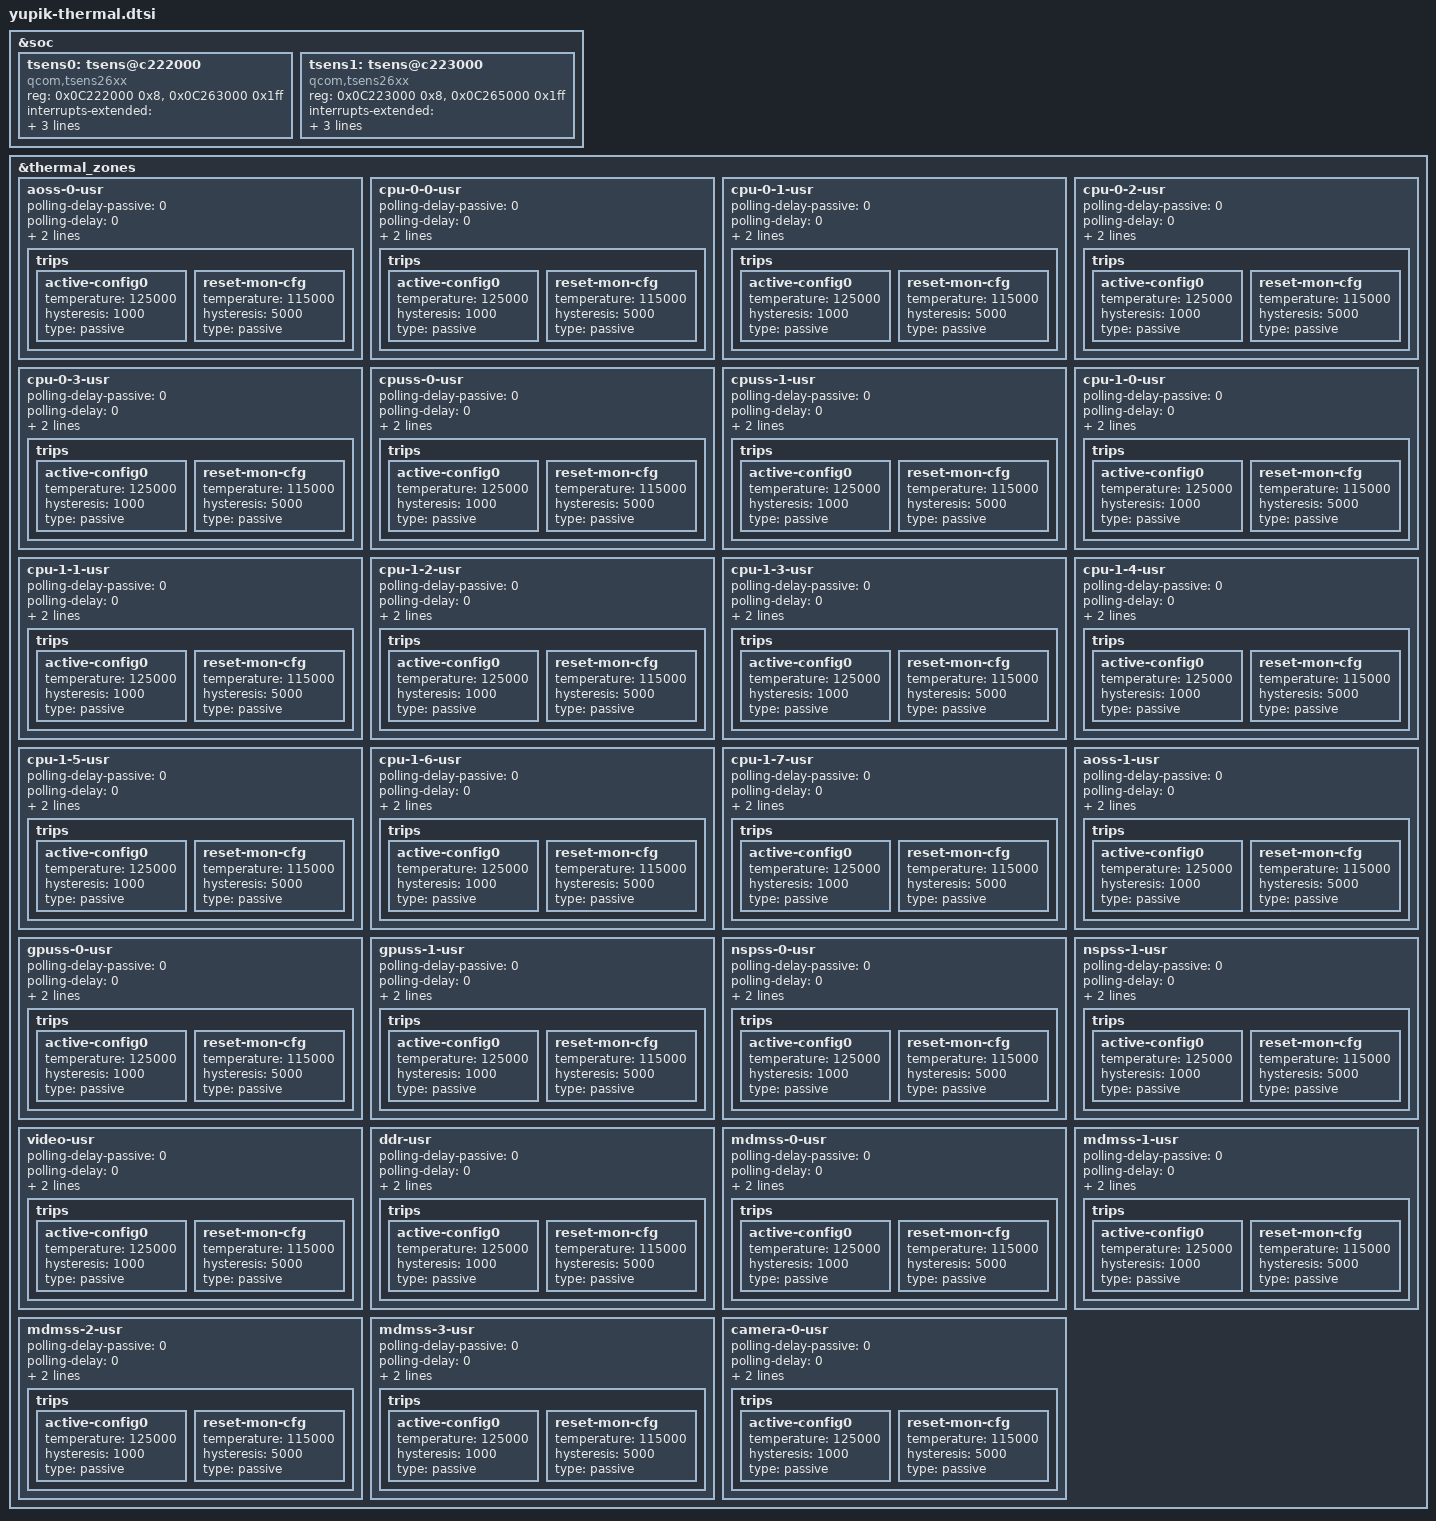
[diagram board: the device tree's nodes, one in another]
#include <dt-bindings/thermal/thermal_qti.h>

&soc {
	tsens0:tsens@c222000 {
		compatible = "qcom,tsens26xx";
		reg = <0x0C222000 0x8>,
			<0x0C263000 0x1ff>;
		reg-names = "tsens_srot_physical",
			"tsens_tm_physical";
		interrupts-extended = <&intc GIC_SPI 506 IRQ_TYPE_LEVEL_HIGH>,
				<&intc GIC_SPI 508 IRQ_TYPE_LEVEL_HIGH>,
				<&pdc 20 IRQ_TYPE_EDGE_RISING>;
		interrupt-names = "tsens-upper-lower",
				"tsens-critical",
				"tsens-0C";
		#thermal-sensor-cells = <1>;
	};

	tsens1:tsens@c223000 {
		compatible = "qcom,tsens26xx";
		reg = <0x0C223000 0x8>,
			<0x0C265000 0x1ff>;
		reg-names = "tsens_srot_physical",
			"tsens_tm_physical";
		interrupts-extended = <&intc GIC_SPI 507 IRQ_TYPE_LEVEL_HIGH>,
				<&intc GIC_SPI 509 IRQ_TYPE_LEVEL_HIGH>,
				<&pdc 21 IRQ_TYPE_EDGE_RISING>;
		interrupt-names = "tsens-upper-lower",
				"tsens-critical",
				"tsens-0C";
		#thermal-sensor-cells = <1>;
	};
};

&thermal_zones {
	aoss-0-usr {
		polling-delay-passive = <0>;
		polling-delay = <0>;
		thermal-governor = "user_space";
		thermal-sensors = <&tsens0 0>;
		trips {
			active-config0 {
				temperature = <125000>;
				hysteresis = <1000>;
				type = "passive";
			};

			reset-mon-cfg {
				temperature = <115000>;
				hysteresis = <5000>;
				type = "passive";
			};
		};
	};

	cpu-0-0-usr {
		polling-delay-passive = <0>;
		polling-delay = <0>;
		thermal-governor = "user_space";
		thermal-sensors = <&tsens0 1>;
		trips {
			active-config0 {
				temperature = <125000>;
				hysteresis = <1000>;
				type = "passive";
			};

			reset-mon-cfg {
				temperature = <115000>;
				hysteresis = <5000>;
				type = "passive";
			};
		};
	};

	cpu-0-1-usr {
		polling-delay-passive = <0>;
		polling-delay = <0>;
		thermal-governor = "user_space";
		thermal-sensors = <&tsens0 2>;
		trips {
			active-config0 {
				temperature = <125000>;
				hysteresis = <1000>;
				type = "passive";
			};

			reset-mon-cfg {
				temperature = <115000>;
				hysteresis = <5000>;
				type = "passive";
			};
		};
	};

	cpu-0-2-usr {
		polling-delay-passive = <0>;
		polling-delay = <0>;
		thermal-governor = "user_space";
		thermal-sensors = <&tsens0 3>;
		trips {
			active-config0 {
				temperature = <125000>;
				hysteresis = <1000>;
				type = "passive";
			};

			reset-mon-cfg {
				temperature = <115000>;
				hysteresis = <5000>;
				type = "passive";
			};
		};
	};

	cpu-0-3-usr {
		polling-delay-passive = <0>;
		polling-delay = <0>;
		thermal-governor = "user_space";
		thermal-sensors = <&tsens0 4>;
		trips {
			active-config0 {
				temperature = <125000>;
				hysteresis = <1000>;
				type = "passive";
			};

			reset-mon-cfg {
				temperature = <115000>;
				hysteresis = <5000>;
				type = "passive";
			};
		};
	};

	cpuss-0-usr {
		polling-delay-passive = <0>;
		polling-delay = <0>;
		thermal-governor = "user_space";
		thermal-sensors = <&tsens0 5>;
		trips {
			active-config0 {
				temperature = <125000>;
				hysteresis = <1000>;
				type = "passive";
			};

			reset-mon-cfg {
				temperature = <115000>;
				hysteresis = <5000>;
				type = "passive";
			};
		};
	};

	cpuss-1-usr {
		polling-delay-passive = <0>;
		polling-delay = <0>;
		thermal-governor = "user_space";
		thermal-sensors = <&tsens0 6>;
		trips {
			active-config0 {
				temperature = <125000>;
				hysteresis = <1000>;
				type = "passive";
			};

			reset-mon-cfg {
				temperature = <115000>;
				hysteresis = <5000>;
				type = "passive";
			};
		};
	};

	cpu-1-0-usr {
		polling-delay-passive = <0>;
		polling-delay = <0>;
		thermal-governor = "user_space";
		thermal-sensors = <&tsens0 7>;
		trips {
			active-config0 {
				temperature = <125000>;
				hysteresis = <1000>;
				type = "passive";
			};

			reset-mon-cfg {
				temperature = <115000>;
				hysteresis = <5000>;
				type = "passive";
			};
		};
	};

	cpu-1-1-usr {
		polling-delay-passive = <0>;
		polling-delay = <0>;
		thermal-governor = "user_space";
		thermal-sensors = <&tsens0 8>;
		trips {
			active-config0 {
				temperature = <125000>;
				hysteresis = <1000>;
				type = "passive";
			};

			reset-mon-cfg {
				temperature = <115000>;
				hysteresis = <5000>;
				type = "passive";
			};
		};
	};

	cpu-1-2-usr {
		polling-delay-passive = <0>;
		polling-delay = <0>;
		thermal-governor = "user_space";
		thermal-sensors = <&tsens0 9>;
		trips {
			active-config0 {
				temperature = <125000>;
				hysteresis = <1000>;
				type = "passive";
			};

			reset-mon-cfg {
				temperature = <115000>;
				hysteresis = <5000>;
				type = "passive";
			};
		};
	};

	cpu-1-3-usr {
		polling-delay-passive = <0>;
		polling-delay = <0>;
		thermal-governor = "user_space";
		thermal-sensors = <&tsens0 10>;
		trips {
			active-config0 {
				temperature = <125000>;
				hysteresis = <1000>;
				type = "passive";
			};

			reset-mon-cfg {
				temperature = <115000>;
				hysteresis = <5000>;
				type = "passive";
			};
		};
	};

	cpu-1-4-usr {
		polling-delay-passive = <0>;
		polling-delay = <0>;
		thermal-governor = "user_space";
		thermal-sensors = <&tsens0 11>;
		trips {
			active-config0 {
				temperature = <125000>;
				hysteresis = <1000>;
				type = "passive";
			};

			reset-mon-cfg {
				temperature = <115000>;
				hysteresis = <5000>;
				type = "passive";
			};
		};
	};

	cpu-1-5-usr {
		polling-delay-passive = <0>;
		polling-delay = <0>;
		thermal-governor = "user_space";
		thermal-sensors = <&tsens0 12>;
		trips {
			active-config0 {
				temperature = <125000>;
				hysteresis = <1000>;
				type = "passive";
			};

			reset-mon-cfg {
				temperature = <115000>;
				hysteresis = <5000>;
				type = "passive";
			};
		};
	};

	cpu-1-6-usr {
		polling-delay-passive = <0>;
		polling-delay = <0>;
		thermal-governor = "user_space";
		thermal-sensors = <&tsens0 13>;
		trips {
			active-config0 {
				temperature = <125000>;
				hysteresis = <1000>;
				type = "passive";
			};

			reset-mon-cfg {
				temperature = <115000>;
				hysteresis = <5000>;
				type = "passive";
			};
		};
	};

	cpu-1-7-usr {
		polling-delay-passive = <0>;
		polling-delay = <0>;
		thermal-governor = "user_space";
		thermal-sensors = <&tsens0 14>;
		trips {
			active-config0 {
				temperature = <125000>;
				hysteresis = <1000>;
				type = "passive";
			};

			reset-mon-cfg {
				temperature = <115000>;
				hysteresis = <5000>;
				type = "passive";
			};
		};
	};

	aoss-1-usr {
		polling-delay-passive = <0>;
		polling-delay = <0>;
		thermal-governor = "user_space";
		thermal-sensors = <&tsens1 0>;
		trips {
			active-config0 {
				temperature = <125000>;
				hysteresis = <1000>;
				type = "passive";
			};

			reset-mon-cfg {
				temperature = <115000>;
				hysteresis = <5000>;
				type = "passive";
			};
		};
	};

	gpuss-0-usr {
		polling-delay-passive = <0>;
		polling-delay = <0>;
		thermal-governor = "user_space";
		thermal-sensors = <&tsens1 1>;
		trips {
			active-config0 {
				temperature = <125000>;
				hysteresis = <1000>;
				type = "passive";
			};

			reset-mon-cfg {
				temperature = <115000>;
				hysteresis = <5000>;
				type = "passive";
			};
		};
	};

	gpuss-1-usr {
		polling-delay-passive = <0>;
		polling-delay = <0>;
		thermal-governor = "user_space";
		thermal-sensors = <&tsens1 2>;
		trips {
			active-config0 {
				temperature = <125000>;
				hysteresis = <1000>;
				type = "passive";
			};

			reset-mon-cfg {
				temperature = <115000>;
				hysteresis = <5000>;
				type = "passive";
			};
		};
	};

	nspss-0-usr {
		polling-delay-passive = <0>;
		polling-delay = <0>;
		thermal-governor = "user_space";
		thermal-sensors = <&tsens1 3>;
		trips {
			active-config0 {
				temperature = <125000>;
				hysteresis = <1000>;
				type = "passive";
			};

			reset-mon-cfg {
				temperature = <115000>;
				hysteresis = <5000>;
				type = "passive";
			};
		};
	};

	nspss-1-usr {
		polling-delay-passive = <0>;
		polling-delay = <0>;
		thermal-governor = "user_space";
		thermal-sensors = <&tsens1 4>;
		trips {
			active-config0 {
				temperature = <125000>;
				hysteresis = <1000>;
				type = "passive";
			};

			reset-mon-cfg {
				temperature = <115000>;
				hysteresis = <5000>;
				type = "passive";
			};
		};
	};

	video-usr {
		polling-delay-passive = <0>;
		polling-delay = <0>;
		thermal-governor = "user_space";
		thermal-sensors = <&tsens1 5>;
		trips {
			active-config0 {
				temperature = <125000>;
				hysteresis = <1000>;
				type = "passive";
			};

			reset-mon-cfg {
				temperature = <115000>;
				hysteresis = <5000>;
				type = "passive";
			};
		};
	};

	ddr-usr {
		polling-delay-passive = <0>;
		polling-delay = <0>;
		thermal-governor = "user_space";
		thermal-sensors = <&tsens1 6>;
		trips {
			active-config0 {
				temperature = <125000>;
				hysteresis = <1000>;
				type = "passive";
			};

			reset-mon-cfg {
				temperature = <115000>;
				hysteresis = <5000>;
				type = "passive";
			};
		};
	};

	mdmss-0-usr {
		polling-delay-passive = <0>;
		polling-delay = <0>;
		thermal-governor = "user_space";
		thermal-sensors = <&tsens1 7>;
		trips {
			active-config0 {
				temperature = <125000>;
				hysteresis = <1000>;
				type = "passive";
			};

			reset-mon-cfg {
				temperature = <115000>;
				hysteresis = <5000>;
				type = "passive";
			};
		};
	};

	mdmss-1-usr {
		polling-delay-passive = <0>;
		polling-delay = <0>;
		thermal-governor = "user_space";
		thermal-sensors = <&tsens1 8>;
		trips {
			active-config0 {
				temperature = <125000>;
				hysteresis = <1000>;
				type = "passive";
			};

			reset-mon-cfg {
				temperature = <115000>;
				hysteresis = <5000>;
				type = "passive";
			};
		};
	};

	mdmss-2-usr {
		polling-delay-passive = <0>;
		polling-delay = <0>;
		thermal-governor = "user_space";
		thermal-sensors = <&tsens1 9>;
		trips {
			active-config0 {
				temperature = <125000>;
				hysteresis = <1000>;
				type = "passive";
			};

			reset-mon-cfg {
				temperature = <115000>;
				hysteresis = <5000>;
				type = "passive";
			};
		};
	};

	mdmss-3-usr {
		polling-delay-passive = <0>;
		polling-delay = <0>;
		thermal-governor = "user_space";
		thermal-sensors = <&tsens1 10>;
		trips {
			active-config0 {
				temperature = <125000>;
				hysteresis = <1000>;
				type = "passive";
			};

			reset-mon-cfg {
				temperature = <115000>;
				hysteresis = <5000>;
				type = "passive";
			};
		};
	};

	camera-0-usr {
		polling-delay-passive = <0>;
		polling-delay = <0>;
		thermal-governor = "user_space";
		thermal-sensors = <&tsens1 11>;
		trips {
			active-config0 {
				temperature = <125000>;
				hysteresis = <1000>;
				type = "passive";
			};

			reset-mon-cfg {
				temperature = <115000>;
				hysteresis = <5000>;
				type = "passive";
			};
		};
	};
};

